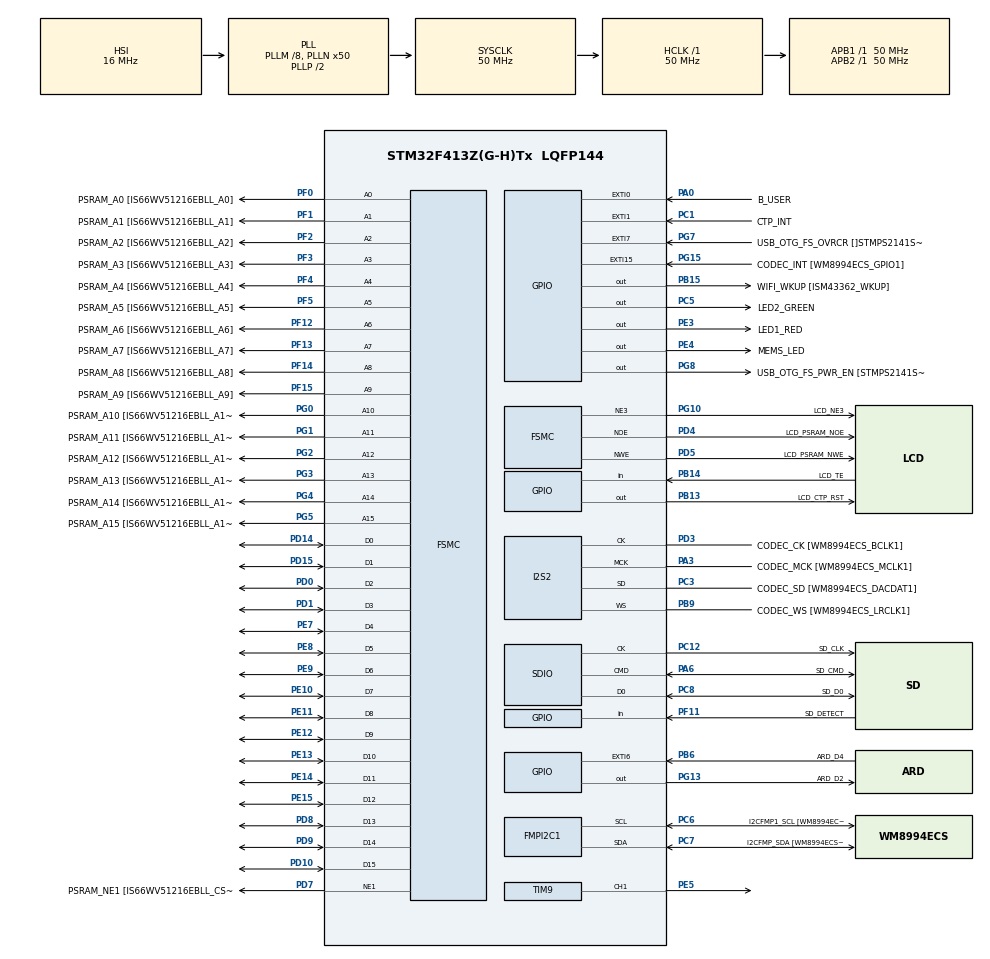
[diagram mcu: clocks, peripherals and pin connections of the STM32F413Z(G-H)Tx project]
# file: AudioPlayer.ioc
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Dma.Request0=SPI2_TX
Dma.SPI2_TX.0.Direction=DMA_MEMORY_TO_PERIPH
Dma.SPI2_TX.0.FIFOMode=DMA_FIFOMODE_DISABLE
Dma.SPI2_TX.0.Instance=DMA1_Stream4
Dma.SPI2_TX.0.MemDataAlignment=DMA_MDATAALIGN_HALFWORD
Dma.SPI2_TX.0.MemInc=DMA_MINC_ENABLE
Dma.SPI2_TX.0.Mode=DMA_CIRCULAR
Dma.SPI2_TX.0.PeriphDataAlignment=DMA_PDATAALIGN_HALFWORD
Dma.SPI2_TX.0.PeriphInc=DMA_PINC_DISABLE
Dma.SPI2_TX.0.Priority=DMA_PRIORITY_LOW
FATFS.BSP.number=1
FATFS._USE_LFN=1
FATFS0.BSP.STBoard=false
FATFS0.BSP.api=Unknown
FATFS0.BSP.i2caddr=0
FATFS0.BSP.instance=PF11
FATFS0.BSP.ip=GPIO
FATFS0.BSP.mode=Input
FATFS0.BSP.name=Detect_SDIO
FATFS0.BSP.solution=PF11
FMPI2C1.Timing=0x00C0EAFF
FSMC.AddressSetupTime1=3
FSMC.BusTurnAroundDuration1=1
FSMC.DataSetupTime1=4
FSMC.ExtendedAddressSetupTime1=3
FSMC.ExtendedBusTurnAroundDuration1=1
FSMC.ExtendedDataSetupTime1=4
FSMC.ExtendedMode1=FSMC_EXTENDED_MODE_ENABLE
FSMC.ExtendedMode2=FSMC_EXTENDED_MODE_ENABLE
FSMC.WriteFifo1=FSMC_WRITE_FIFO_DISABLE
FSMC.WriteFifo2=FSMC_WRITE_FIFO_DISABLE
FSMC.WriteFifo3=FSMC_WRITE_FIFO_DISABLE
FSMC.WriteFifo4=FSMC_WRITE_FIFO_DISABLE
FSMC.WriteOperation1=FSMC_WRITE_OPERATION_ENABLE
FSMC.WriteOperation2=FSMC_WRITE_OPERATION_ENABLE
I2S2.AudioFreq=I2S_AUDIOFREQ_44K
I2S2.ErrorAudioFreq=-0.12 %
I2S2.FullDuplexMode=I2S_FULLDUPLEXMODE_DISABLE
I2S2.Instance=SPI$Index
I2S2.RealAudioFreq=43.945 KHz
I2S2.VirtualMode=I2S_MODE_MASTER
LPTIM1.ClockPrescaler=LPTIM_PRESCALER_DIV128
Mcu.Family=STM32F4
Mcu.Name=STM32F413Z(G-H)Tx
Mcu.Package=LQFP144
NVIC.DMA1_Stream4_IRQn=true\:0\:0\:false\:false\:true\:false\:true
NVIC.EXTI1_IRQn=true\:0\:0\:false\:false\:true\:true\:true
NVIC.LPTIM1_IRQn=true\:0\:0\:false\:false\:true\:true\:true
NVIC.PriorityGroup=NVIC_PRIORITYGROUP_4
NVIC.SPI2_IRQn=true\:0\:0\:false\:false\:true\:true\:true
PA0.GPIO_Label=B_USER
PA0.Signal=GPXTI0
PA1.GPIO_Label=ARD_A1
PA1.Signal=ADCx_IN1
PA10.GPIO_Label=USB_OTG_FS_ID
PA10.Signal=USB_OTG_FS_ID
PA11.GPIO_Label=USB_OTG_FS_DM
PA11.Signal=USB_OTG_FS_DM
PA12.GPIO_Label=USB_OTG_FS_DP
PA12.Signal=USB_OTG_FS_DP
PA13.GPIO_Label=STLINK_JTMS_SWDIO
PA13.Signal=SYS_JTMS-SWDIO
PA14.GPIO_Label=STLINK_JTMS_SWCLK
PA14.Signal=SYS_JTCK-SWCLK
PA15.GPIO_Label=ARD_D10
PA15.Signal=S_TIM2_CH1_ETR
PA2.GPIO_Label=ARD_A2
PA2.Signal=ADCx_IN2
PA3.GPIO_Label=CODEC_MCK [WM8994ECS_MCLK1]
PA3.Mode=Master_Clock_Activated
PA3.Signal=I2S2_MCK
PA4.GPIO_Label=ARD_D8
PA4.Signal=COMP_DAC1_group
PA5.GPIO_Label=ARD_A3
PA5.Signal=ADCx_IN5
PA6.GPIO_Label=SD_CMD
PA6.Mode=SD_1_bit
PA6.Signal=SDIO_CMD
PA7.GPIO_Label=DFSDM2_DATIN1
PA7.Signal=S_DATAIN1DFSDM2
PA8.GPIO_Label=DFSDM1_CKOUT
PA8.Signal=S_CKOUTDFSDM1
PA9.GPIO_Label=USB_OTG_FS_VBUS
PA9.Signal=USB_OTG_FS_VBUS
PB0.GPIO_Label=ARD_D6
PB0.Signal=S_TIM3_CH3
PB1.GPIO_Label=ARD_A4
PB1.Signal=ADCx_IN9
PB10.GPIO_Label=ARD_D15
PB10.Signal=I2C2_SCL
PB11.GPIO_Label=ARD_D14
PB11.Signal=I2C2_SDA
PB12.GPIO_Label=ARD_D13 [ISM43362_SCK]
PB12.Signal=SPI3_SCK
PB13.GPIO_Label=LCD_CTP_RST
PB13.GPIO_Speed=GPIO_SPEED_FREQ_HIGH
PB13.Signal=GPIO_Output
PB14.GPIO_Label=LCD_TE
PB14.Signal=GPIO_Input
PB15.GPIO_Label=WIFI_WKUP [ISM43362_WKUP]
PB15.Signal=GPIO_Output
PB2.GPIO_Label=QSPI_CLK [N25Q128A13EF840F_C]
PB2.Signal=QUADSPI_CLK
PB3.GPIO_Label=STLINK_JTDO_SWCLK
PB3.Signal=SYS_JTDO-SWO
PB4.GPIO_Label=ARD_D12 [ISM43362_MISO]
PB4.Signal=SPI3_MISO
PB5.GPIO_Label=ARD_D11 [ISM43362_MOSI]
PB5.Signal=SPI3_MOSI
PB6.GPIO_Label=ARD_D4
PB6.Signal=GPXTI6
PB7.GPIO_Label=DFSDM2_DATIN7
PB7.Signal=S_DATAIN7DFSDM2
PB8.GPIO_Label=ARD_D9
PB8.Signal=S_TIM4_CH3
PB9.GPIO_Label=CODEC_WS [WM8994ECS_LRCLK1]
PB9.Mode=Half_Duplex_Master
PB9.Signal=I2S2_WS
PC0.GPIO_Label=ARD_A0
PC0.Signal=ADCx_IN10
PC1.GPIO_Label=CTP_INT
PC1.GPIO_ModeDefaultEXTI=GPIO_MODE_IT_RISING_FALLING
PC1.GPIO_PuPd=GPIO_NOPULL
PC1.Signal=GPXTI1
PC10.GPIO_Label=SD_D2
PC10.GPIO_PuPd=GPIO_PULLUP
PC10.Signal=SDIO_D2
PC11.GPIO_Label=SD_D3
PC11.GPIO_PuPd=GPIO_PULLUP
PC11.Signal=SDIO_D3
PC12.GPIO_Label=SD_CLK
PC12.Mode=SD_1_bit
PC12.Signal=SDIO_CK
PC14-OSC32_IN.GPIO_Label=OSC32_IN
PC14-OSC32_IN.Mode=LSE-External-Oscillator
PC14-OSC32_IN.Signal=RCC_OSC32_IN
PC15-OSC32_OUT.GPIO_Label=OSC32_OUT
PC15-OSC32_OUT.Mode=LSE-External-Oscillator
PC15-OSC32_OUT.Signal=RCC_OSC32_OUT
PC2.GPIO_Label=CODEC_ext_SD [WM8994ECS_ADC_DAT1]
PC2.Signal=I2S2_ext_SD
PC3.GPIO_Label=CODEC_SD [WM8994ECS_DACDAT1]
PC3.Mode=Half_Duplex_Master
PC3.Signal=I2S2_SD
PC4.GPIO_Label=ARD_A5
PC4.Signal=ADCx_IN14
PC5.GPIO_Label=LED2_GREEN
PC5.Signal=GPIO_Output
PC6.GPIO_Label=I2CFMP1_SCL [WM8994ECS_CLK]
PC6.Mode=I2C
PC6.Signal=FMPI2C1_SCL
PC7.GPIO_Label=I2CFMP_SDA [WM8994ECS_SDA]
PC7.Mode=I2C
PC7.Signal=FMPI2C1_SDA
PC8.GPIO_Label=SD_D0
PC8.GPIO_PuPd=GPIO_PULLUP
PC8.Mode=SD_1_bit
PC8.Signal=SDIO_D0
PC9.GPIO_Label=SD_D1
PC9.GPIO_PuPd=GPIO_PULLUP
PC9.Signal=SDIO_D1
PD0.GPIO_PuPd=GPIO_PULLUP
PD0.Signal=FSMC_D2_DA2
PD1.GPIO_PuPd=GPIO_PULLUP
PD1.Signal=FSMC_D3_DA3
PD10.Signal=FSMC_D15_DA15
PD11.GPIO_Label=PSRAM_A16 [IS66WV51216EBLL_A16]
PD11.GPIO_PuPd=GPIO_PULLUP
PD11.Signal=FSMC_A16
PD12.GPIO_Label=PSRAM_A17 [IS66WV51216EBLL_A17]
PD12.GPIO_PuPd=GPIO_PULLUP
PD12.Signal=FSMC_A17
PD13.GPIO_Label=QSPI_BK1_IO3 [N25Q128A13EF840F_DQ3]
PD13.Signal=QUADSPI_BK1_IO3
PD14.Signal=FSMC_D0_DA0
PD15.Signal=FSMC_D1_DA1
PD2.GPIO_Label=DFSDM2_CKOUT
PD2.Signal=S_CKOUTDFSDM2
PD3.GPIO_Label=CODEC_CK [WM8994ECS_BCLK1]
PD3.Mode=Half_Duplex_Master
PD3.Signal=I2S2_CK
PD4.GPIO_Label=LCD_PSRAM_NOE
PD4.GPIO_PuPd=GPIO_PULLUP
PD4.Signal=FSMC_NOE
PD5.GPIO_Label=LCD_PSRAM_NWE
PD5.GPIO_PuPd=GPIO_PULLUP
PD5.Signal=FSMC_NWE
PD6.GPIO_Label=DFSDM1_DATIN1
PD6.Signal=S_DATAIN1DFSDM1
PD7.GPIO_Label=PSRAM_NE1 [IS66WV51216EBLL_CS1]
PD7.GPIO_PuPd=GPIO_PULLUP
PD7.Mode=NorPsramChipSelect1_2
PD7.Signal=FSMC_NE1
PD8.Signal=FSMC_D13_DA13
PD9.Signal=FSMC_D14_DA14
PE0.GPIO_Label=PSRAM_NBL0 [IS66WV51216EBLL_LB]
PE0.Signal=FSMC_NBL0
PE1.GPIO_Label=PSRAM_NBL1 [IS66WV51216EBLL_UB]
PE1.Signal=FSMC_NBL1
PE10.GPIO_PuPd=GPIO_PULLUP
PE10.Signal=FSMC_D7_DA7
PE11.GPIO_PuPd=GPIO_PULLUP
PE11.Signal=FSMC_D8_DA8
PE12.GPIO_PuPd=GPIO_PULLUP
PE12.Signal=FSMC_D9_DA9
PE13.GPIO_PuPd=GPIO_PULLUP
PE13.Signal=FSMC_D10_DA10
PE14.GPIO_PuPd=GPIO_PULLUP
PE14.Signal=FSMC_D11_DA11
PE15.GPIO_PuPd=GPIO_PULLUP
PE15.Signal=FSMC_D12_DA12
PE2.GPIO_Label=QSPI_BK1_IO2 [N25Q128A13EF840F_DQ2]
PE2.Signal=QUADSPI_BK1_IO2
PE3.GPIO_Label=LED1_RED
PE3.Signal=GPIO_Output
PE4.GPIO_Label=MEMS_LED
PE4.Signal=GPIO_Output
PE5.Signal=S_TIM9_CH1
PE6.GPIO_Label=ARD_D5
PE6.Signal=S_TIM9_CH2
PE7.Signal=FSMC_D4_DA4
PE8.Signal=FSMC_D5_DA5
PE9.GPIO_PuPd=GPIO_PULLUP
PE9.Signal=FSMC_D6_DA6
PF0.GPIO_Label=PSRAM_A0 [IS66WV51216EBLL_A0]
PF0.GPIO_PuPd=GPIO_PULLUP
PF0.Signal=FSMC_A0
PF1.GPIO_Label=PSRAM_A1 [IS66WV51216EBLL_A1]
PF1.GPIO_PuPd=GPIO_PULLUP
PF1.Signal=FSMC_A1
PF10.GPIO_Label=ARD_D3
PF10.Signal=S_TIM5_CH4
PF11.GPIO_Label=SD_DETECT
PF11.GPIO_PuPd=GPIO_PULLUP
PF11.Signal=GPIO_Input
PF12.GPIO_Label=PSRAM_A6 [IS66WV51216EBLL_A6]
PF12.GPIO_PuPd=GPIO_PULLUP
PF12.Signal=FSMC_A6
PF13.GPIO_Label=PSRAM_A7 [IS66WV51216EBLL_A7]
PF13.GPIO_PuPd=GPIO_PULLUP
PF13.Signal=FSMC_A7
PF14.GPIO_Label=PSRAM_A8 [IS66WV51216EBLL_A8]
PF14.GPIO_PuPd=GPIO_PULLUP
PF14.Signal=FSMC_A8
PF15.GPIO_Label=PSRAM_A9 [IS66WV51216EBLL_A9]
PF15.GPIO_PuPd=GPIO_PULLUP
PF15.Signal=FSMC_A9
PF2.GPIO_Label=PSRAM_A2 [IS66WV51216EBLL_A2]
PF2.GPIO_PuPd=GPIO_PULLUP
PF2.Signal=FSMC_A2
PF3.GPIO_Label=PSRAM_A3 [IS66WV51216EBLL_A3]
PF3.GPIO_PuPd=GPIO_PULLUP
PF3.Signal=FSMC_A3
PF4.GPIO_Label=PSRAM_A4 [IS66WV51216EBLL_A4]
PF4.GPIO_PuPd=GPIO_PULLUP
PF4.Signal=FSMC_A4
PF5.GPIO_Label=PSRAM_A5 [IS66WV51216EBLL_A5]
PF5.GPIO_PuPd=GPIO_PULLUP
PF5.Signal=FSMC_A5
PF6.GPIO_Label=ARD_D0
PF6.Signal=UART7_RX
PF7.GPIO_Label=ARD_D1
PF7.Signal=UART7_TX
PF8.GPIO_Label=QSPI_BK1_IO0 [N25Q128A13EF840F_DQ0]
PF8.Signal=QUADSPI_BK1_IO0
PF9.GPIO_Label=QSPI_BK1_IO1 [N25Q128A13EF840F_DQ1]
PF9.Signal=QUADSPI_BK1_IO1
PG0.GPIO_Label=PSRAM_A10 [IS66WV51216EBLL_A10]
PG0.GPIO_PuPd=GPIO_PULLUP
PG0.Signal=FSMC_A10
PG1.GPIO_Label=PSRAM_A11 [IS66WV51216EBLL_A11]
PG1.GPIO_PuPd=GPIO_PULLUP
PG1.Signal=FSMC_A11
PG10.GPIO_Label=LCD_NE3
PG10.GPIO_PuPd=GPIO_PULLUP
PG10.Mode=NorPsramChipSelect3_1
PG10.Signal=FSMC_NE3
PG11.GPIO_Label=WIFI_SPI_CSN [ISM43362_SPI_CS]
PG11.Signal=UART10_RX
PG12.GPIO_Label=WIFI_DRDY [ISM43362_DRDY]
PG12.Signal=UART10_TX
PG13.GPIO_Label=ARD_D2
PG13.Signal=GPIO_Output
PG14.GPIO_Label=VCP_TX
PG14.Signal=USART6_TX
PG15.GPIO_Label=CODEC_INT [WM8994ECS_GPIO1]
PG15.Signal=GPXTI15
PG2.GPIO_Label=PSRAM_A12 [IS66WV51216EBLL_A12]
PG2.GPIO_PuPd=GPIO_PULLUP
PG2.Signal=FSMC_A12
PG3.GPIO_Label=PSRAM_A13 [IS66WV51216EBLL_A13]
PG3.GPIO_PuPd=GPIO_PULLUP
PG3.Signal=FSMC_A13
PG4.GPIO_Label=PSRAM_A14 [IS66WV51216EBLL_A14]
PG4.GPIO_PuPd=GPIO_PULLUP
PG4.Signal=FSMC_A14
PG5.GPIO_Label=PSRAM_A15 [IS66WV51216EBLL_A15]
PG5.GPIO_PuPd=GPIO_PULLUP
PG5.Signal=FSMC_A15
PG6.GPIO_Label=QSPI_BK1_NCS [N25Q128A13EF840F_S]
PG6.Signal=QUADSPI_BK1_NCS
PG7.GPIO_Label=USB_OTG_FS_OVRCR []STMPS2141STR_FAULT]
PG7.Signal=GPXTI7
PG8.GPIO_Label=USB_OTG_FS_PWR_EN [STMPS2141STR_EN]
PG8.Signal=GPIO_Output
PG9.GPIO_Label=VCP_RX
PG9.Signal=USART6_RX
PH0\ -\ OSC_IN.GPIO_Label=STLK_MCO
PH0\ -\ OSC_IN.Signal=RCC_OSC_IN
ProjectManager.HeapSize=0x200
ProjectManager.StackSize=0x400
ProjectManager.TargetToolchain=STM32CubeIDE
RCC.AHBFreq_Value=50000000
RCC.APB1Freq_Value=50000000
RCC.APB1TimFreq_Value=50000000
RCC.APB2Freq_Value=50000000
RCC.APB2TimFreq_Value=50000000
RCC.CortexFreq_Value=50000000
RCC.HCLKFreq_Value=50000000
RCC.HSE_VALUE=8000000
RCC.LPTIM1CLockSelection=RCC_LPTIM1CLKSOURCE_LSE
RCC.LockedElements=SDIOoutput,LPTimeroutput,I2S1output
RCC.PLLI2SM=8
RCC.PLLI2SN=90
RCC.PLLM=8
RCC.PLLN=50
RCC.PLLQ=4
RCC.RCC_RTC_Clock_Source=RCC_RTCCLKSOURCE_LSE
RCC.RCC_RTC_Clock_SourceVirtual=RCC_RTCCLKSOURCE_LSE
RCC.SYSCLKFreq_VALUE=50000000
RCC.SYSCLKSource=RCC_SYSCLKSOURCE_PLLCLK
RCC.USBFreq_Value=25000000
RCC.VCOOutputFreq_Value=100000000
SDIO.ClockBypass=SDIO_CLOCK_BYPASS_DISABLE
SDIO.ClockDiv=0
SH.ADCx_IN1.0=ADC1_IN1
SH.ADCx_IN10.0=ADC1_IN10
SH.ADCx_IN14.0=ADC1_IN14
SH.ADCx_IN2.0=ADC1_IN2
SH.ADCx_IN5.0=ADC1_IN5
SH.ADCx_IN9.0=ADC1_IN9
SH.COMP_DAC1_group.0=DAC_OUT1
SH.FSMC_A0.0=FSMC_A0,16b-a1
SH.FSMC_A0.1=FSMC_A0,16b-a2
SH.FSMC_A1.0=FSMC_A1,16b-a1
SH.FSMC_A1.1=FSMC_A1,16b-a2
SH.FSMC_A10.0=FSMC_A10,16b-a1
SH.FSMC_A10.1=FSMC_A10,16b-a2
SH.FSMC_A11.0=FSMC_A11,16b-a1
SH.FSMC_A11.1=FSMC_A11,16b-a2
SH.FSMC_A12.0=FSMC_A12,16b-a1
SH.FSMC_A12.1=FSMC_A12,16b-a2
SH.FSMC_A13.0=FSMC_A13,16b-a1
SH.FSMC_A13.1=FSMC_A13,16b-a2
SH.FSMC_A14.0=FSMC_A14,16b-a1
SH.FSMC_A14.1=FSMC_A14,16b-a2
SH.FSMC_A15.0=FSMC_A15,16b-a1
SH.FSMC_A15.1=FSMC_A15,16b-a2
SH.FSMC_A16.0=FSMC_A16
SH.FSMC_A17.0=FSMC_A17
SH.FSMC_A2.0=FSMC_A2,16b-a1
SH.FSMC_A2.1=FSMC_A2,16b-a2
SH.FSMC_A3.0=FSMC_A3,16b-a1
SH.FSMC_A3.1=FSMC_A3,16b-a2
SH.FSMC_A4.0=FSMC_A4,16b-a1
SH.FSMC_A4.1=FSMC_A4,16b-a2
SH.FSMC_A5.0=FSMC_A5,16b-a1
SH.FSMC_A5.1=FSMC_A5,16b-a2
SH.FSMC_A6.0=FSMC_A6,16b-a1
SH.FSMC_A6.1=FSMC_A6,16b-a2
SH.FSMC_A7.0=FSMC_A7,16b-a1
SH.FSMC_A7.1=FSMC_A7,16b-a2
SH.FSMC_A8.0=FSMC_A8,16b-a1
SH.FSMC_A8.1=FSMC_A8,16b-a2
SH.FSMC_A9.0=FSMC_A9,16b-a1
SH.FSMC_A9.1=FSMC_A9,16b-a2
SH.FSMC_D0_DA0.0=FSMC_D0,16b-d1
SH.FSMC_D0_DA0.1=FSMC_DA0
SH.FSMC_D0_DA0.2=FSMC_D0,16b-d2
SH.FSMC_D10_DA10.0=FSMC_D10,16b-d1
SH.FSMC_D10_DA10.1=FSMC_DA10
SH.FSMC_D10_DA10.2=FSMC_D10,16b-d2
SH.FSMC_D11_DA11.0=FSMC_D11,16b-d1
SH.FSMC_D11_DA11.1=FSMC_DA11
SH.FSMC_D11_DA11.2=FSMC_D11,16b-d2
SH.FSMC_D12_DA12.0=FSMC_D12,16b-d1
SH.FSMC_D12_DA12.1=FSMC_DA12
SH.FSMC_D12_DA12.2=FSMC_D12,16b-d2
SH.FSMC_D13_DA13.0=FSMC_D13,16b-d1
SH.FSMC_D13_DA13.1=FSMC_DA13
SH.FSMC_D13_DA13.2=FSMC_D13,16b-d2
SH.FSMC_D14_DA14.0=FSMC_D14,16b-d1
SH.FSMC_D14_DA14.1=FSMC_DA14
SH.FSMC_D14_DA14.2=FSMC_D14,16b-d2
SH.FSMC_D15_DA15.0=FSMC_D15,16b-d1
SH.FSMC_D15_DA15.1=FSMC_DA15
SH.FSMC_D15_DA15.2=FSMC_D15,16b-d2
SH.FSMC_D1_DA1.0=FSMC_D1,16b-d1
SH.FSMC_D1_DA1.1=FSMC_DA1
SH.FSMC_D1_DA1.2=FSMC_D1,16b-d2
SH.FSMC_D2_DA2.0=FSMC_D2,16b-d1
SH.FSMC_D2_DA2.1=FSMC_DA2
SH.FSMC_D2_DA2.2=FSMC_D2,16b-d2
SH.FSMC_D3_DA3.0=FSMC_D3,16b-d1
SH.FSMC_D3_DA3.1=FSMC_DA3
SH.FSMC_D3_DA3.2=FSMC_D3,16b-d2
SH.FSMC_D4_DA4.0=FSMC_D4,16b-d1
SH.FSMC_D4_DA4.1=FSMC_DA4
SH.FSMC_D4_DA4.2=FSMC_D4,16b-d2
SH.FSMC_D5_DA5.0=FSMC_D5,16b-d1
SH.FSMC_D5_DA5.1=FSMC_DA5
SH.FSMC_D5_DA5.2=FSMC_D5,16b-d2
SH.FSMC_D6_DA6.0=FSMC_D6,16b-d1
SH.FSMC_D6_DA6.1=FSMC_DA6
SH.FSMC_D6_DA6.2=FSMC_D6,16b-d2
SH.FSMC_D7_DA7.0=FSMC_D7,16b-d1
SH.FSMC_D7_DA7.1=FSMC_DA7
SH.FSMC_D7_DA7.2=FSMC_D7,16b-d2
SH.FSMC_D8_DA8.0=FSMC_D8,16b-d1
SH.FSMC_D8_DA8.1=FSMC_DA8
SH.FSMC_D8_DA8.2=FSMC_D8,16b-d2
SH.FSMC_D9_DA9.0=FSMC_D9,16b-d1
SH.FSMC_D9_DA9.1=FSMC_DA9
SH.FSMC_D9_DA9.2=FSMC_D9,16b-d2
SH.FSMC_NBL0.0=FSMC_NBL0
SH.FSMC_NBL1.0=FSMC_NBL1
SH.FSMC_NOE.0=FSMC_NOE,Sram1
SH.FSMC_NOE.1=FSMC_NOE,Psram2
SH.FSMC_NWE.0=FSMC_NWE,Sram1
SH.FSMC_NWE.1=FSMC_NWE,Psram2
SH.S_CKOUTDFSDM1.0=DFSDM1_CKOUT
SH.S_CKOUTDFSDM2.0=DFSDM2_CKOUT
SH.S_DATAIN1DFSDM1.0=DFSDM1_DATIN1
SH.S_DATAIN1DFSDM2.0=DFSDM2_DATIN1
SH.S_DATAIN7DFSDM2.0=DFSDM2_DATIN7
SH.S_TIM2_CH1_ETR.0=TIM2_CH1
SH.S_TIM3_CH3.0=TIM3_CH3
SH.S_TIM4_CH3.0=TIM4_CH3
SH.S_TIM5_CH4.0=TIM5_CH4
SH.S_TIM9_CH1.0=TIM9_CH1,PWM Generation1 CH1
SH.S_TIM9_CH2.0=TIM9_CH2
TIM9.Channel-PWM\ Generation1\ CH1=TIM_CHANNEL_1
TIM9.ClockDivision=TIM_CLOCKDIVISION_DIV4
TIM9.OCMode_PWM-PWM\ Generation1\ CH1=TIM_OCMODE_PWM1
TIM9.Period=999
TIM9.Prescaler=1000
VP_FATFS_VS_SDIO.Mode=SDIO
VP_LPTIM1_VS_LPTIM_counterModeInternalClock.Mode=Counts__internal_clock_event_00
VP_RTC_VS_RTC_Activate.Mode=RTC_Enabled
VP_RTC_VS_RTC_Calendar.Mode=RTC_Calendar
board=STM32F413H-DISCO

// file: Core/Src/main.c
/* USER CODE BEGIN Header */
/**
  ******************************************************************************
  * @file           : main.c
  * @brief          : Main program body
  ******************************************************************************
  * @attention
  *
  * <h2><center>&copy; Copyright (c) 2020 STMicroelectronics.
  * All rights reserved.</center></h2>
  *
  * This software component is licensed by ST under Ultimate Liberty license
  * SLA0044, the "License"; You may not use this file except in compliance with
  * the License. You may obtain a copy of the License at:
  *                             www.st.com/SLA0044
  *
  ******************************************************************************
  */
/* USER CODE END Header */
#include "main.h"
#include "fatfs.h"

FMPI2C_HandleTypeDef hfmpi2c1;

I2S_HandleTypeDef hi2s2;
DMA_HandleTypeDef hdma_spi2_tx;

LPTIM_HandleTypeDef hlptim1;

RTC_HandleTypeDef hrtc;

SD_HandleTypeDef hsd;

TIM_HandleTypeDef htim9;

SRAM_HandleTypeDef hsram1;
SRAM_HandleTypeDef hsram2;

FIL file;
uint8_t sound[8172];
unsigned int br;

char** filenames;
int files_size = 0;
int file_index;

void SystemClock_Config(void);
static void MX_GPIO_Init(void);
static void MX_DMA_Init(void);
static void MX_I2S2_Init(void);
static void MX_FMPI2C1_Init(void);
static void MX_SDIO_SD_Init(void);
static void MX_TIM9_Init(void);
static void MX_FSMC_Init(void);
static void MX_LPTIM1_Init(void);
static void MX_RTC_Init(void);

/* USER CODE BEGIN 0 */
extern void main_cpp();
/* USER CODE END 0 */

int main(void)
{

  /* MCU Configuration--------------------------------------------------------*/

  /* Reset of all peripherals, Initializes the Flash interface and the Systick. */
  HAL_Init();

  /* Configure the system clock */
  SystemClock_Config();

  /* Initialize all configured peripherals */
  MX_GPIO_Init();
  MX_DMA_Init();
  MX_I2S2_Init();
  MX_FMPI2C1_Init();
  MX_SDIO_SD_Init();
  MX_FATFS_Init();
  MX_TIM9_Init();
  MX_FSMC_Init();
  MX_LPTIM1_Init();
  MX_RTC_Init();
  /* USER CODE BEGIN 2 */

  	  main_cpp();
  /* USER CODE END 2 */

  /* Infinite loop */
  while (1)
  {

  }
}

void SystemClock_Config(void)
{
  RCC_OscInitTypeDef RCC_OscInitStruct = {0};
  RCC_ClkInitTypeDef RCC_ClkInitStruct = {0};
  RCC_PeriphCLKInitTypeDef PeriphClkInitStruct = {0};

  /** Configure the main internal regulator output voltage
  */
  __HAL_RCC_PWR_CLK_ENABLE();
  __HAL_PWR_VOLTAGESCALING_CONFIG(PWR_REGULATOR_VOLTAGE_SCALE1);
  /** Initializes the RCC Oscillators according to the specified parameters
  * in the RCC_OscInitTypeDef structure.
  */
  RCC_OscInitStruct.OscillatorType = RCC_OSCILLATORTYPE_HSI|RCC_OSCILLATORTYPE_LSE;
  RCC_OscInitStruct.LSEState = RCC_LSE_ON;
  RCC_OscInitStruct.HSIState = RCC_HSI_ON;
  RCC_OscInitStruct.HSICalibrationValue = RCC_HSICALIBRATION_DEFAULT;
  RCC_OscInitStruct.PLL.PLLState = RCC_PLL_ON;
  RCC_OscInitStruct.PLL.PLLSource = RCC_PLLSOURCE_HSI;
  RCC_OscInitStruct.PLL.PLLM = 8;
  RCC_OscInitStruct.PLL.PLLN = 50;
  RCC_OscInitStruct.PLL.PLLP = RCC_PLLP_DIV2;
  RCC_OscInitStruct.PLL.PLLQ = 4;
  RCC_OscInitStruct.PLL.PLLR = 2;
  if (HAL_RCC_OscConfig(&RCC_OscInitStruct) != HAL_OK)
  {
    Error_Handler();
  }
  /** Initializes the CPU, AHB and APB buses clocks
  */
  RCC_ClkInitStruct.ClockType = RCC_CLOCKTYPE_HCLK|RCC_CLOCKTYPE_SYSCLK
                              |RCC_CLOCKTYPE_PCLK1|RCC_CLOCKTYPE_PCLK2;
  RCC_ClkInitStruct.SYSCLKSource = RCC_SYSCLKSOURCE_PLLCLK;
  RCC_ClkInitStruct.AHBCLKDivider = RCC_SYSCLK_DIV1;
  RCC_ClkInitStruct.APB1CLKDivider = RCC_HCLK_DIV1;
  RCC_ClkInitStruct.APB2CLKDivider = RCC_HCLK_DIV1;

  if (HAL_RCC_ClockConfig(&RCC_ClkInitStruct, FLASH_LATENCY_1) != HAL_OK)
  {
    Error_Handler();
  }
  PeriphClkInitStruct.PeriphClockSelection = RCC_PERIPHCLK_I2S_APB1|RCC_PERIPHCLK_RTC
                              |RCC_PERIPHCLK_SDIO|RCC_PERIPHCLK_CLK48
                              |RCC_PERIPHCLK_FMPI2C1|RCC_PERIPHCLK_LPTIM1;
  PeriphClkInitStruct.PLLI2S.PLLI2SN = 90;
  PeriphClkInitStruct.PLLI2S.PLLI2SM = 8;
  PeriphClkInitStruct.PLLI2S.PLLI2SR = 2;
  PeriphClkInitStruct.PLLI2S.PLLI2SQ = 2;
  PeriphClkInitStruct.RTCClockSelection = RCC_RTCCLKSOURCE_LSE;
  PeriphClkInitStruct.Clk48ClockSelection = RCC_CLK48CLKSOURCE_PLLQ;
  PeriphClkInitStruct.SdioClockSelection = RCC_SDIOCLKSOURCE_CLK48;
  PeriphClkInitStruct.PLLI2SSelection = RCC_PLLI2SCLKSOURCE_PLLSRC;
  PeriphClkInitStruct.I2sApb1ClockSelection = RCC_I2SAPB1CLKSOURCE_PLLI2S;
  PeriphClkInitStruct.Fmpi2c1ClockSelection = RCC_FMPI2C1CLKSOURCE_APB;
  PeriphClkInitStruct.Lptim1ClockSelection = RCC_LPTIM1CLKSOURCE_LSE;
  if (HAL_RCCEx_PeriphCLKConfig(&PeriphClkInitStruct) != HAL_OK)
  {
    Error_Handler();
  }
}

static void MX_FMPI2C1_Init(void)
{

  hfmpi2c1.Instance = FMPI2C1;
  hfmpi2c1.Init.Timing = 0x00C0EAFF;
  hfmpi2c1.Init.OwnAddress1 = 0;
  hfmpi2c1.Init.AddressingMode = FMPI2C_ADDRESSINGMODE_7BIT;
  hfmpi2c1.Init.DualAddressMode = FMPI2C_DUALADDRESS_DISABLE;
  hfmpi2c1.Init.OwnAddress2 = 0;
  hfmpi2c1.Init.OwnAddress2Masks = FMPI2C_OA2_NOMASK;
  hfmpi2c1.Init.GeneralCallMode = FMPI2C_GENERALCALL_DISABLE;
  hfmpi2c1.Init.NoStretchMode = FMPI2C_NOSTRETCH_DISABLE;
  if (HAL_FMPI2C_Init(&hfmpi2c1) != HAL_OK)
  {
    Error_Handler();
  }
  /** Configure Analogue filter
  */
  if (HAL_FMPI2CEx_ConfigAnalogFilter(&hfmpi2c1, FMPI2C_ANALOGFILTER_ENABLE) != HAL_OK)
  {
    Error_Handler();
  }

}

static void MX_I2S2_Init(void)
{

  hi2s2.Instance = SPI2;
  hi2s2.Init.Mode = I2S_MODE_MASTER_TX;
  hi2s2.Init.Standard = I2S_STANDARD_PHILIPS;
  hi2s2.Init.DataFormat = I2S_DATAFORMAT_16B;
  hi2s2.Init.MCLKOutput = I2S_MCLKOUTPUT_ENABLE;
  hi2s2.Init.AudioFreq = I2S_AUDIOFREQ_44K;
  hi2s2.Init.CPOL = I2S_CPOL_LOW;
  hi2s2.Init.ClockSource = I2S_CLOCK_PLL;
  hi2s2.Init.FullDuplexMode = I2S_FULLDUPLEXMODE_DISABLE;
  if (HAL_I2S_Init(&hi2s2) != HAL_OK)
  {
    Error_Handler();
  }

}

static void MX_LPTIM1_Init(void)
{

  hlptim1.Instance = LPTIM1;
  hlptim1.Init.Clock.Source = LPTIM_CLOCKSOURCE_APBCLOCK_LPOSC;
  hlptim1.Init.Clock.Prescaler = LPTIM_PRESCALER_DIV128;
  hlptim1.Init.Trigger.Source = LPTIM_TRIGSOURCE_SOFTWARE;
  hlptim1.Init.OutputPolarity = LPTIM_OUTPUTPOLARITY_HIGH;
  hlptim1.Init.UpdateMode = LPTIM_UPDATE_IMMEDIATE;
  hlptim1.Init.CounterSource = LPTIM_COUNTERSOURCE_INTERNAL;
  if (HAL_LPTIM_Init(&hlptim1) != HAL_OK)
  {
    Error_Handler();
  }
  __HAL_LPTIM_OPTR_CONFIG(&hlptim1, LPTIM_OP_PAD_AF);
  /* USER CODE BEGIN LPTIM1_Init 2 */
  __HAL_RCC_LPTIM1_CLK_SLEEP_ENABLE();
  /* USER CODE END LPTIM1_Init 2 */

}

static void MX_RTC_Init(void)
{

  RTC_TimeTypeDef sTime = {0};
  RTC_DateTypeDef sDate = {0};

  /** Initialize RTC Only
  */
  hrtc.Instance = RTC;
  hrtc.Init.HourFormat = RTC_HOURFORMAT_24;
  hrtc.Init.AsynchPrediv = 127;
  hrtc.Init.SynchPrediv = 255;
  hrtc.Init.OutPut = RTC_OUTPUT_DISABLE;
  hrtc.Init.OutPutPolarity = RTC_OUTPUT_POLARITY_HIGH;
  hrtc.Init.OutPutType = RTC_OUTPUT_TYPE_OPENDRAIN;
  if (HAL_RTC_Init(&hrtc) != HAL_OK)
  {
    Error_Handler();
  }

  /** Initialize RTC and set the Time and Date
  */
  sTime.Hours = 0x0;
  sTime.Minutes = 0x0;
  sTime.Seconds = 0x0;
  sTime.DayLightSaving = RTC_DAYLIGHTSAVING_NONE;
  sTime.StoreOperation = RTC_STOREOPERATION_RESET;
  if (HAL_RTC_SetTime(&hrtc, &sTime, RTC_FORMAT_BCD) != HAL_OK)
  {
    Error_Handler();
  }
  sDate.WeekDay = RTC_WEEKDAY_MONDAY;
  sDate.Month = RTC_MONTH_JANUARY;
  sDate.Date = 0x1;
  sDate.Year = 0x0;

  if (HAL_RTC_SetDate(&hrtc, &sDate, RTC_FORMAT_BCD) != HAL_OK)
  {
    Error_Handler();
  }

}

static void MX_SDIO_SD_Init(void)
{

  hsd.Instance = SDIO;
  hsd.Init.ClockEdge = SDIO_CLOCK_EDGE_RISING;
  hsd.Init.ClockBypass = SDIO_CLOCK_BYPASS_DISABLE;
  hsd.Init.ClockPowerSave = SDIO_CLOCK_POWER_SAVE_DISABLE;
  hsd.Init.BusWide = SDIO_BUS_WIDE_1B;
  hsd.Init.HardwareFlowControl = SDIO_HARDWARE_FLOW_CONTROL_DISABLE;
  hsd.Init.ClockDiv = 0;

}

static void MX_TIM9_Init(void)
{

  TIM_OC_InitTypeDef sConfigOC = {0};

  htim9.Instance = TIM9;
  htim9.Init.Prescaler = 1000;
  htim9.Init.CounterMode = TIM_COUNTERMODE_UP;
  htim9.Init.Period = 999;
  htim9.Init.ClockDivision = TIM_CLOCKDIVISION_DIV4;
  htim9.Init.AutoReloadPreload = TIM_AUTORELOAD_PRELOAD_DISABLE;
  if (HAL_TIM_PWM_Init(&htim9) != HAL_OK)
  {
    Error_Handler();
  }
  sConfigOC.OCMode = TIM_OCMODE_PWM1;
  sConfigOC.Pulse = 0;
  sConfigOC.OCPolarity = TIM_OCPOLARITY_HIGH;
  sConfigOC.OCFastMode = TIM_OCFAST_DISABLE;
  if (HAL_TIM_PWM_ConfigChannel(&htim9, &sConfigOC, TIM_CHANNEL_1) != HAL_OK)
  {
    Error_Handler();
  }
  HAL_TIM_MspPostInit(&htim9);

}

static void MX_DMA_Init(void)
{

  /* DMA controller clock enable */
  __HAL_RCC_DMA1_CLK_ENABLE();

  /* DMA interrupt init */
  /* DMA1_Stream4_IRQn interrupt configuration */
  HAL_NVIC_SetPriority(DMA1_Stream4_IRQn, 0, 0);
  HAL_NVIC_EnableIRQ(DMA1_Stream4_IRQn);

}

static void MX_GPIO_Init(void)
{
  GPIO_InitTypeDef GPIO_InitStruct = {0};

  /* GPIO Ports Clock Enable */
  __HAL_RCC_GPIOE_CLK_ENABLE();
  __HAL_RCC_GPIOC_CLK_ENABLE();
  __HAL_RCC_GPIOF_CLK_ENABLE();
  __HAL_RCC_GPIOH_CLK_ENABLE();
  __HAL_RCC_GPIOA_CLK_ENABLE();
  __HAL_RCC_GPIOB_CLK_ENABLE();
  __HAL_RCC_GPIOG_CLK_ENABLE();
  __HAL_RCC_GPIOD_CLK_ENABLE();

  /*Configure GPIO pin Output Level */
  HAL_GPIO_WritePin(GPIOE, LED1_RED_Pin|MEMS_LED_Pin, GPIO_PIN_RESET);

  /*Configure GPIO pin Output Level */
  HAL_GPIO_WritePin(LED2_GREEN_GPIO_Port, LED2_GREEN_Pin, GPIO_PIN_RESET);

  /*Configure GPIO pin Output Level */
  HAL_GPIO_WritePin(GPIOB, LCD_CTP_RST_Pin|WIFI_WKUP_Pin, GPIO_PIN_RESET);

  /*Configure GPIO pin Output Level */
  HAL_GPIO_WritePin(GPIOG, USB_OTG_FS_PWR_EN_Pin|ARD_D2_Pin, GPIO_PIN_RESET);

  /*Configure GPIO pin : QSPI_BK1_IO2_Pin */
  GPIO_InitStruct.Pin = QSPI_BK1_IO2_Pin;
  GPIO_InitStruct.Mode = GPIO_MODE_AF_PP;
  GPIO_InitStruct.Pull = GPIO_NOPULL;
  GPIO_InitStruct.Speed = GPIO_SPEED_FREQ_VERY_HIGH;
  GPIO_InitStruct.Alternate = GPIO_AF9_QSPI;
  HAL_GPIO_Init(QSPI_BK1_IO2_GPIO_Port, &GPIO_InitStruct);

  /*Configure GPIO pins : LED1_RED_Pin MEMS_LED_Pin */
  GPIO_InitStruct.Pin = LED1_RED_Pin|MEMS_LED_Pin;
  GPIO_InitStruct.Mode = GPIO_MODE_OUTPUT_PP;
  GPIO_InitStruct.Pull = GPIO_NOPULL;
  GPIO_InitStruct.Speed = GPIO_SPEED_FREQ_LOW;
  HAL_GPIO_Init(GPIOE, &GPIO_InitStruct);

  /*Configure GPIO pins : QSPI_BK1_IO0_Pin QSPI_BK1_IO1_Pin */
  GPIO_InitStruct.Pin = QSPI_BK1_IO0_Pin|QSPI_BK1_IO1_Pin;
  GPIO_InitStruct.Mode = GPIO_MODE_AF_PP;
  GPIO_InitStruct.Pull = GPIO_NOPULL;
  GPIO_InitStruct.Speed = GPIO_SPEED_FREQ_VERY_HIGH;
  GPIO_InitStruct.Alternate = GPIO_AF10_OTG_FS;
  HAL_GPIO_Init(GPIOF, &GPIO_InitStruct);

  /*Configure GPIO pin : ARD_D3_Pin */
  GPIO_InitStruct.Pin = ARD_D3_Pin;
  GPIO_InitStruct.Mode = GPIO_MODE_AF_PP;
  GPIO_InitStruct.Pull = GPIO_NOPULL;
  GPIO_InitStruct.Speed = GPIO_SPEED_FREQ_LOW;
  GPIO_InitStruct.Alternate = GPIO_AF2_TIM5;
  HAL_GPIO_Init(ARD_D3_GPIO_Port, &GPIO_InitStruct);

  /*Configure GPIO pins : ARD_A0_Pin ARD_A5_Pin */
  GPIO_InitStruct.Pin = ARD_A0_Pin|ARD_A5_Pin;
  GPIO_InitStruct.Mode = GPIO_MODE_ANALOG;
  GPIO_InitStruct.Pull = GPIO_NOPULL;
  HAL_GPIO_Init(GPIOC, &GPIO_InitStruct);

  /*Configure GPIO pin : CTP_INT_Pin */
  GPIO_InitStruct.Pin = CTP_INT_Pin;
  GPIO_InitStruct.Mode = GPIO_MODE_IT_RISING_FALLING;
  GPIO_InitStruct.Pull = GPIO_NOPULL;
  HAL_GPIO_Init(CTP_INT_GPIO_Port, &GPIO_InitStruct);

  /*Configure GPIO pin : B_USER_Pin */
  GPIO_InitStruct.Pin = B_USER_Pin;
  GPIO_InitStruct.Mode = GPIO_MODE_IT_RISING;
  GPIO_InitStruct.Pull = GPIO_NOPULL;
  HAL_GPIO_Init(B_USER_GPIO_Port, &GPIO_InitStruct);

  /*Configure GPIO pins : ARD_A1_Pin ARD_A2_Pin ARD_D8_Pin ARD_A3_Pin */
  GPIO_InitStruct.Pin = ARD_A1_Pin|ARD_A2_Pin|ARD_D8_Pin|ARD_A3_Pin;
  GPIO_InitStruct.Mode = GPIO_MODE_ANALOG;
  GPIO_InitStruct.Pull = GPIO_NOPULL;
  HAL_GPIO_Init(GPIOA, &GPIO_InitStruct);

  /*Configure GPIO pin : DFSDM2_DATIN1_Pin */
  GPIO_InitStruct.Pin = DFSDM2_DATIN1_Pin;
  GPIO_InitStruct.Mode = GPIO_MODE_AF_PP;
  GPIO_InitStruct.Pull = GPIO_NOPULL;
  GPIO_InitStruct.Speed = GPIO_SPEED_FREQ_LOW;
  GPIO_InitStruct.Alternate = GPIO_AF7_DFSDM2;
  HAL_GPIO_Init(DFSDM2_DATIN1_GPIO_Port, &GPIO_InitStruct);

  /*Configure GPIO pin : LED2_GREEN_Pin */
  GPIO_InitStruct.Pin = LED2_GREEN_Pin;
  GPIO_InitStruct.Mode = GPIO_MODE_OUTPUT_PP;
  GPIO_InitStruct.Pull = GPIO_NOPULL;
  GPIO_InitStruct.Speed = GPIO_SPEED_FREQ_LOW;
  HAL_GPIO_Init(LED2_GREEN_GPIO_Port, &GPIO_InitStruct);

  /*Configure GPIO pin : ARD_D6_Pin */
  GPIO_InitStruct.Pin = ARD_D6_Pin;
  GPIO_InitStruct.Mode = GPIO_MODE_AF_PP;
  GPIO_InitStruct.Pull = GPIO_NOPULL;
  GPIO_InitStruct.Speed = GPIO_SPEED_FREQ_LOW;
  GPIO_InitStruct.Alternate = GPIO_AF2_TIM3;
  HAL_GPIO_Init(ARD_D6_GPIO_Port, &GPIO_InitStruct);

  /*Configure GPIO pin : ARD_A4_Pin */
  GPIO_InitStruct.Pin = ARD_A4_Pin;
  GPIO_InitStruct.Mode = GPIO_MODE_ANALOG;
  GPIO_InitStruct.Pull = GPIO_NOPULL;
  HAL_GPIO_Init(ARD_A4_GPIO_Port, &GPIO_InitStruct);

  /*Configure GPIO pin : QSPI_CLK_Pin */
  GPIO_InitStruct.Pin = QSPI_CLK_Pin;
  GPIO_InitStruct.Mode = GPIO_MODE_AF_PP;
  GPIO_InitStruct.Pull = GPIO_NOPULL;
  GPIO_InitStruct.Speed = GPIO_SPEED_FREQ_VERY_HIGH;
  GPIO_InitStruct.Alternate = GPIO_AF9_QSPI;
  HAL_GPIO_Init(QSPI_CLK_GPIO_Port, &GPIO_InitStruct);

  /*Configure GPIO pin : SD_DETECT_Pin */
  GPIO_InitStruct.Pin = SD_DETECT_Pin;
  GPIO_InitStruct.Mode = GPIO_MODE_INPUT;
  GPIO_InitStruct.Pull = GPIO_PULLUP;
  HAL_GPIO_Init(SD_DETECT_GPIO_Port, &GPIO_InitStruct);

  /*Configure GPIO pins : ARD_D15_Pin ARD_D14_Pin */
  GPIO_InitStruct.Pin = ARD_D15_Pin|ARD_D14_Pin;
  GPIO_InitStruct.Mode = GPIO_MODE_AF_OD;
  GPIO_InitStruct.Pull = GPIO_PULLUP;
  GPIO_InitStruct.Speed = GPIO_SPEED_FREQ_VERY_HIGH;
  GPIO_InitStruct.Alternate = GPIO_AF4_I2C2;
  HAL_GPIO_Init(GPIOB, &GPIO_InitStruct);

  /*Configure GPIO pin : ARD_D13_Pin */
  GPIO_InitStruct.Pin = ARD_D13_Pin;
  GPIO_InitStruct.Mode = GPIO_MODE_AF_PP;
  GPIO_InitStruct.Pull = GPIO_NOPULL;
  GPIO_InitStruct.Speed = GPIO_SPEED_FREQ_VERY_HIGH;
  GPIO_InitStruct.Alternate = GPIO_AF7_SPI3;
  HAL_GPIO_Init(ARD_D13_GPIO_Port, &GPIO_InitStruct);

  /*Configure GPIO pin : LCD_CTP_RST_Pin */
  GPIO_InitStruct.Pin = LCD_CTP_RST_Pin;
  GPIO_InitStruct.Mode = GPIO_MODE_OUTPUT_PP;
  GPIO_InitStruct.Pull = GPIO_NOPULL;
  GPIO_InitStruct.Speed = GPIO_SPEED_FREQ_HIGH;
  HAL_GPIO_Init(LCD_CTP_RST_GPIO_Port, &GPIO_InitStruct);

  /*Configure GPIO pin : LCD_TE_Pin */
  GPIO_InitStruct.Pin = LCD_TE_Pin;
  GPIO_InitStruct.Mode = GPIO_MODE_INPUT;
  GPIO_InitStruct.Pull = GPIO_NOPULL;
  HAL_GPIO_Init(LCD_TE_GPIO_Port, &GPIO_InitStruct);

  /*Configure GPIO pin : WIFI_WKUP_Pin */
  GPIO_InitStruct.Pin = WIFI_WKUP_Pin;
  GPIO_InitStruct.Mode = GPIO_MODE_OUTPUT_PP;
  GPIO_InitStruct.Pull = GPIO_NOPULL;
  GPIO_InitStruct.Speed = GPIO_SPEED_FREQ_LOW;
  HAL_GPIO_Init(WIFI_WKUP_GPIO_Port, &GPIO_InitStruct);

  /*Configure GPIO pin : QSPI_BK1_IO3_Pin */
  GPIO_InitStruct.Pin = QSPI_BK1_IO3_Pin;
  GPIO_InitStruct.Mode = GPIO_MODE_AF_PP;
  GPIO_InitStruct.Pull = GPIO_NOPULL;
  GPIO_InitStruct.Speed = GPIO_SPEED_FREQ_VERY_HIGH;
  GPIO_InitStruct.Alternate = GPIO_AF9_QSPI;
  HAL_GPIO_Init(QSPI_BK1_IO3_GPIO_Port, &GPIO_InitStruct);

  /*Configure GPIO pin : QSPI_BK1_NCS_Pin */
  GPIO_InitStruct.Pin = QSPI_BK1_NCS_Pin;
  GPIO_InitStruct.Mode = GPIO_MODE_AF_PP;
  GPIO_InitStruct.Pull = GPIO_NOPULL;
  GPIO_InitStruct.Speed = GPIO_SPEED_FREQ_VERY_HIGH;
  GPIO_InitStruct.Alternate = GPIO_AF10_OTG_FS;
  HAL_GPIO_Init(QSPI_BK1_NCS_GPIO_Port, &GPIO_InitStruct);

  /*Configure GPIO pins : USB_OTG_FS_OVRCR_Pin CODEC_INT_Pin */
  GPIO_InitStruct.Pin = USB_OTG_FS_OVRCR_Pin|CODEC_INT_Pin;
  GPIO_InitStruct.Mode = GPIO_MODE_IT_RISING;
  GPIO_InitStruct.Pull = GPIO_NOPULL;
  HAL_GPIO_Init(GPIOG, &GPIO_InitStruct);

  /*Configure GPIO pins : USB_OTG_FS_PWR_EN_Pin ARD_D2_Pin */
  GPIO_InitStruct.Pin = USB_OTG_FS_PWR_EN_Pin|ARD_D2_Pin;
  GPIO_InitStruct.Mode = GPIO_MODE_OUTPUT_PP;
  GPIO_InitStruct.Pull = GPIO_NOPULL;
  GPIO_InitStruct.Speed = GPIO_SPEED_FREQ_LOW;
  HAL_GPIO_Init(GPIOG, &GPIO_InitStruct);

  /*Configure GPIO pin : DFSDM1_CKOUT_Pin */
  GPIO_InitStruct.Pin = DFSDM1_CKOUT_Pin;
  GPIO_InitStruct.Mode = GPIO_MODE_AF_PP;
  GPIO_InitStruct.Pull = GPIO_NOPULL;
  GPIO_InitStruct.Speed = GPIO_SPEED_FREQ_LOW;
  GPIO_InitStruct.Alternate = GPIO_AF6_DFSDM1;
  HAL_GPIO_Init(DFSDM1_CKOUT_GPIO_Port, &GPIO_InitStruct);

  /*Configure GPIO pins : USB_OTG_FS_ID_Pin USB_OTG_FS_DM_Pin USB_OTG_FS_DP_Pin */
  GPIO_InitStruct.Pin = USB_OTG_FS_ID_Pin|USB_OTG_FS_DM_Pin|USB_OTG_FS_DP_Pin;
  GPIO_InitStruct.Mode = GPIO_MODE_AF_PP;
  GPIO_InitStruct.Pull = GPIO_NOPULL;
  GPIO_InitStruct.Speed = GPIO_SPEED_FREQ_VERY_HIGH;
  GPIO_InitStruct.Alternate = GPIO_AF10_OTG_FS;
  HAL_GPIO_Init(GPIOA, &GPIO_InitStruct);

  /*Configure GPIO pin : ARD_D10_Pin */
  GPIO_InitStruct.Pin = ARD_D10_Pin;
  GPIO_InitStruct.Mode = GPIO_MODE_AF_PP;
  GPIO_InitStruct.Pull = GPIO_NOPULL;
  GPIO_InitStruct.Speed = GPIO_SPEED_FREQ_LOW;
  GPIO_InitStruct.Alternate = GPIO_AF1_TIM2;
  HAL_GPIO_Init(ARD_D10_GPIO_Port, &GPIO_InitStruct);

  /*Configure GPIO pin : DFSDM2_CKOUT_Pin */
  GPIO_InitStruct.Pin = DFSDM2_CKOUT_Pin;
  GPIO_InitStruct.Mode = GPIO_MODE_AF_PP;
  GPIO_InitStruct.Pull = GPIO_NOPULL;
  GPIO_InitStruct.Speed = GPIO_SPEED_FREQ_LOW;
  GPIO_InitStruct.Alternate = GPIO_AF3_DFSDM2;
  HAL_GPIO_Init(DFSDM2_CKOUT_GPIO_Port, &GPIO_InitStruct);

  /*Configure GPIO pin : DFSDM1_DATIN1_Pin */
  GPIO_InitStruct.Pin = DFSDM1_DATIN1_Pin;
  GPIO_InitStruct.Mode = GPIO_MODE_AF_PP;
  GPIO_InitStruct.Pull = GPIO_NOPULL;
  GPIO_InitStruct.Speed = GPIO_SPEED_FREQ_LOW;
  GPIO_InitStruct.Alternate = GPIO_AF6_DFSDM1;
  HAL_GPIO_Init(DFSDM1_DATIN1_GPIO_Port, &GPIO_InitStruct);

  /*Configure GPIO pins : VCP_RX_Pin VCP_TX_Pin */
  GPIO_InitStruct.Pin = VCP_RX_Pin|VCP_TX_Pin;
  GPIO_InitStruct.Mode = GPIO_MODE_AF_PP;
  GPIO_InitStruct.Pull = GPIO_NOPULL;
  GPIO_InitStruct.Speed = GPIO_SPEED_FREQ_VERY_HIGH;
  GPIO_InitStruct.Alternate = GPIO_AF8_USART6;
  HAL_GPIO_Init(GPIOG, &GPIO_InitStruct);

  /*Configure GPIO pins : ARD_D12_Pin ARD_D11_Pin */
  GPIO_InitStruct.Pin = ARD_D12_Pin|ARD_D11_Pin;
  GPIO_InitStruct.Mode = GPIO_MODE_AF_PP;
  GPIO_InitStruct.Pull = GPIO_NOPULL;
  GPIO_InitStruct.Speed = GPIO_SPEED_FREQ_VERY_HIGH;
  GPIO_InitStruct.Alternate = GPIO_AF6_SPI3;
  HAL_GPIO_Init(GPIOB, &GPIO_InitStruct);

  /*Configure GPIO pin : ARD_D4_Pin */
  GPIO_InitStruct.Pin = ARD_D4_Pin;
  GPIO_InitStruct.Mode = GPIO_MODE_IT_RISING;
  GPIO_InitStruct.Pull = GPIO_NOPULL;
  HAL_GPIO_Init(ARD_D4_GPIO_Port, &GPIO_InitStruct);

  /*Configure GPIO pin : DFSDM2_DATIN7_Pin */
  GPIO_InitStruct.Pin = DFSDM2_DATIN7_Pin;
  GPIO_InitStruct.Mode = GPIO_MODE_AF_PP;
  GPIO_InitStruct.Pull = GPIO_NOPULL;
  GPIO_InitStruct.Speed = GPIO_SPEED_FREQ_LOW;
  GPIO_InitStruct.Alternate = GPIO_AF6_DFSDM2;
  HAL_GPIO_Init(DFSDM2_DATIN7_GPIO_Port, &GPIO_InitStruct);

  /*Configure GPIO pin : ARD_D9_Pin */
  GPIO_InitStruct.Pin = ARD_D9_Pin;
  GPIO_InitStruct.Mode = GPIO_MODE_AF_PP;
  GPIO_InitStruct.Pull = GPIO_NOPULL;
  GPIO_InitStruct.Speed = GPIO_SPEED_FREQ_LOW;
  GPIO_InitStruct.Alternate = GPIO_AF2_TIM4;
  HAL_GPIO_Init(ARD_D9_GPIO_Port, &GPIO_InitStruct);

  /* EXTI interrupt init*/
  HAL_NVIC_SetPriority(EXTI1_IRQn, 0, 0);
  HAL_NVIC_EnableIRQ(EXTI1_IRQn);

}

/* FSMC initialization function */
static void MX_FSMC_Init(void)
{

  FSMC_NORSRAM_TimingTypeDef Timing = {0};
  FSMC_NORSRAM_TimingTypeDef ExtTiming = {0};

  /** Perform the SRAM1 memory initialization sequence
  */
  hsram1.Instance = FSMC_NORSRAM_DEVICE;
  hsram1.Extended = FSMC_NORSRAM_EXTENDED_DEVICE;
  /* hsram1.Init */
  hsram1.Init.NSBank = FSMC_NORSRAM_BANK3;
  hsram1.Init.DataAddressMux = FSMC_DATA_ADDRESS_MUX_DISABLE;
  hsram1.Init.MemoryType = FSMC_MEMORY_TYPE_SRAM;
  hsram1.Init.MemoryDataWidth = FSMC_NORSRAM_MEM_BUS_WIDTH_16;
  hsram1.Init.BurstAccessMode = FSMC_BURST_ACCESS_MODE_DISABLE;
  hsram1.Init.WaitSignalPolarity = FSMC_WAIT_SIGNAL_POLARITY_LOW;
  hsram1.Init.WaitSignalActive = FSMC_WAIT_TIMING_BEFORE_WS;
  hsram1.Init.WriteOperation = FSMC_WRITE_OPERATION_ENABLE;
  hsram1.Init.WaitSignal = FSMC_WAIT_SIGNAL_DISABLE;
  hsram1.Init.ExtendedMode = FSMC_EXTENDED_MODE_ENABLE;
  hsram1.Init.AsynchronousWait = FSMC_ASYNCHRONOUS_WAIT_DISABLE;
  hsram1.Init.WriteBurst = FSMC_WRITE_BURST_DISABLE;
  hsram1.Init.ContinuousClock = FSMC_CONTINUOUS_CLOCK_SYNC_ONLY;
  hsram1.Init.WriteFifo = FSMC_WRITE_FIFO_DISABLE;
  hsram1.Init.PageSize = FSMC_PAGE_SIZE_NONE;
  /* Timing */
  Timing.AddressSetupTime = 3;
  Timing.AddressHoldTime = 15;
  Timing.DataSetupTime = 4;
  Timing.BusTurnAroundDuration = 1;
  Timing.CLKDivision = 16;
  Timing.DataLatency = 17;
  Timing.AccessMode = FSMC_ACCESS_MODE_A;
  /* ExtTiming */
  ExtTiming.AddressSetupTime = 3;
  ExtTiming.AddressHoldTime = 15;
  ExtTiming.DataSetupTime = 4;
  ExtTiming.BusTurnAroundDuration = 1;
  ExtTiming.CLKDivision = 16;
  ExtTiming.DataLatency = 17;
  ExtTiming.AccessMode = FSMC_ACCESS_MODE_A;

  if (HAL_SRAM_Init(&hsram1, &Timing, &ExtTiming) != HAL_OK)
  {
    Error_Handler( );
  }

  /** Perform the SRAM2 memory initialization sequence
  */
  hsram2.Instance = FSMC_NORSRAM_DEVICE;
  hsram2.Extended = FSMC_NORSRAM_EXTENDED_DEVICE;
  /* hsram2.Init */
  hsram2.Init.NSBank = FSMC_NORSRAM_BANK1;
  hsram2.Init.DataAddressMux = FSMC_DATA_ADDRESS_MUX_DISABLE;
  hsram2.Init.MemoryType = FSMC_MEMORY_TYPE_PSRAM;
  hsram2.Init.MemoryDataWidth = FSMC_NORSRAM_MEM_BUS_WIDTH_16;
  hsram2.Init.BurstAccessMode = FSMC_BURST_ACCESS_MODE_DISABLE;
  hsram2.Init.WaitSignalPolarity = FSMC_WAIT_SIGNAL_POLARITY_LOW;
  hsram2.Init.WaitSignalActive = FSMC_WAIT_TIMING_BEFORE_WS;
  hsram2.Init.WriteOperation = FSMC_WRITE_OPERATION_ENABLE;
  hsram2.Init.WaitSignal = FSMC_WAIT_SIGNAL_DISABLE;
  hsram2.Init.ExtendedMode = FSMC_EXTENDED_MODE_ENABLE;
  hsram2.Init.AsynchronousWait = FSMC_ASYNCHRONOUS_WAIT_DISABLE;
  hsram2.Init.WriteBurst = FSMC_WRITE_BURST_DISABLE;
  hsram2.Init.ContinuousClock = FSMC_CONTINUOUS_CLOCK_SYNC_ONLY;
  hsram2.Init.WriteFifo = FSMC_WRITE_FIFO_DISABLE;
  hsram2.Init.PageSize = FSMC_PAGE_SIZE_NONE;
  /* Timing */
  Timing.AddressSetupTime = 15;
  Timing.AddressHoldTime = 15;
  Timing.DataSetupTime = 255;
  Timing.BusTurnAroundDuration = 15;
  Timing.CLKDivision = 16;
  Timing.DataLatency = 17;
  Timing.AccessMode = FSMC_ACCESS_MODE_A;
  /* ExtTiming */
  ExtTiming.AddressSetupTime = 15;
  ExtTiming.AddressHoldTime = 15;
  ExtTiming.DataSetupTime = 255;
  ExtTiming.BusTurnAroundDuration = 15;
  ExtTiming.CLKDivision = 16;
  ExtTiming.DataLatency = 17;
  ExtTiming.AccessMode = FSMC_ACCESS_MODE_A;

  if (HAL_SRAM_Init(&hsram2, &Timing, &ExtTiming) != HAL_OK)
  {
    Error_Handler( );
  }

}

/* USER CODE BEGIN 4 */
void HAL_I2S_TxHalfCpltCallback(I2S_HandleTypeDef *hi2s) {
	if(!f_eof(&file)) {
		f_read(&file, sound, sizeof(sound) / 2, &br);
	}
}

void HAL_I2S_TxCpltCallback(I2S_HandleTypeDef *hi2s) {
	if(!f_eof(&file)) {
		f_read(&file, sound + (sizeof(sound) / 2), sizeof(sound) / 2, &br);
	}
}
/* USER CODE END 4 */

void Error_Handler(void)
{
}

/************************ (C) COPYRIGHT STMicroelectronics *****END OF FILE****/
